# ATmegaS128 device description
Architecture: AVR8; Family: megaAVR
Registers are 8-bit, access not given, no defined reset value unless marked. A register's access mark holds for its fields unless they carry their own. Offsets are from the block's base; [hi:lo] are bit positions; {n}, {i} and the like mark numbered series.

## USART1 — USART
Instances: USART1 0x00
0x98 UBRR1H bits used 3:0 — USART Baud Rate Register High Byte
0x99 UBRR1L — USART Baud Rate Register Low Byte
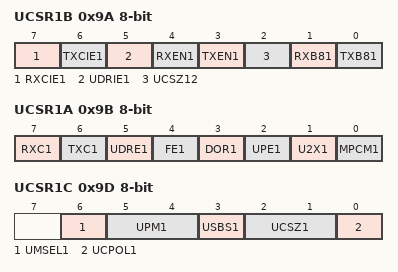
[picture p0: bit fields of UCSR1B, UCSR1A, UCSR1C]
0x9A UCSR1B — USART Control and Status Register B
  [7] RXCIE1 — RX Complete Interrupt Enable
  [6] TXCIE1 — TX Complete Interrupt Enable
  [5] UDRIE1 — USART Data register Empty Interrupt Enable
  [4] RXEN1 — Receiver Enable
  [3] TXEN1 — Transmitter Enable
  [2] UCSZ12 — Character Size
  [1] RXB81 — Receive Data Bit 8
  [0] TXB81 — Transmit Data Bit 8
0x9B UCSR1A — USART Control and Status Register A
  [7] RXC1 — USART Receive Complete
  [6] TXC1 — USART Transmit Complete
  [5] UDRE1 — USART Data Register Empty
  [4] FE1 — Framing Error
  [3] DOR1 — Data overRun
  [2] UPE1 — Parity Error
  [1] U2X1 — Double the USART transmission speed
  [0] MPCM1 — Multi-processor Communication Mode
0x9C UDR1 — USART I/O Data Register
0x9D UCSR1C — USART Control and Status Register C
  [6] UMSEL1 — USART Mode Select
    0=ASYNCHRONOUS_OPERATION; 1=SYNCHRONOUS_OPERATION
  [5:4] UPM1 — Parity Mode Bits
    0=DISABLED; 2=ENABLED_EVEN_PARITY; 3=ENABLED_ODD_PARITY
  [3] USBS1 — Stop Bit Select
    0=1_BIT; 1=2_BIT
  [2:1] UCSZ1 — Character Size
  [0] UCPOL1 — Clock Polarity

## CPU — CPU Registers
Instances: CPU 0x00
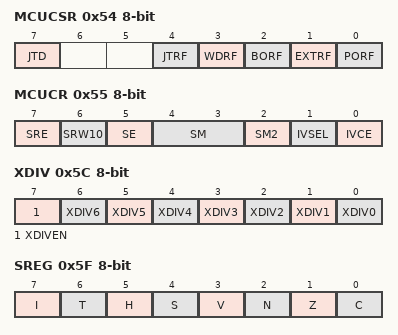
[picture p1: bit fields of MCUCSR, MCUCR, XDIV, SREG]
0x54 MCUCSR — MCU Control And Status Register
  [7] JTD — JTAG Interface Disable
  [4] JTRF — JTAG Reset Flag
  [3] WDRF — Watchdog Reset Flag
  [2] BORF — Brown-out Reset Flag
  [1] EXTRF — External Reset Flag
  [0] PORF — Power-on reset flag
0x55 MCUCR — MCU Control Register
  [7] SRE — External SRAM Enable
  [6] SRW10 — External SRAM Wait State Select
  [5] SE — Sleep Enable
  [4:3] SM — Sleep Mode Select
  [2] SM2 — Sleep Mode Select
    0=IDLE; 2=ADC (ADC Noise Reduction (If Available)); 4=PDOWN (Power Down); 6=PSAVE (Power Save); 5=STDBY (Standby); 7=ESTDBY (Extended Standby)
  [1] IVSEL — Interrupt Vector Select
  [0] IVCE — Interrupt Vector Change Enable
0x5B RAMPZ — RAM Page Z Select Register
  [0] RAMPZ0 — RAM Page Z Select Register Bit 0
0x5C XDIV — XTAL Divide Control Register
  [7] XDIVEN — XTAL Divide Enable
  [n] XDIV{n} (n=0..6) — XTAL Divide Select Bit {n}
0x5D SP 16-bit — Stack Pointer
0x5F SREG — Status Register
  [7] I — Global Interrupt Enable
  [6] T — Bit Copy Storage
  [5] H — Half Carry Flag
  [4] S — Sign Bit
  [3] V — Two's Complement Overflow Flag
  [2] N — Negative Flag
  [1] Z — Zero Flag
  [0] C — Carry Flag
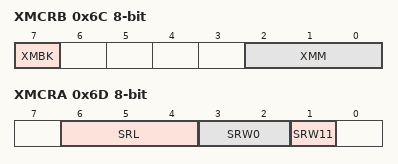
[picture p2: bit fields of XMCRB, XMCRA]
0x6C XMCRB — External Memory Control Register B
  [7] XMBK — External Memory Bus Keeper Enable
  [2:0] XMM — External Memory High Mask
0x6D XMCRA — External Memory Control Register A
  [6:4] SRL — Wait state page limit
    0=LS_N_A_US_0X1100_0XFFFF; 1=LS_0X1100_0X1FFF_US_0X2000_0XFFFF; 2=LS_0X1100_0X3FFF_US_0X4000_0XFFFF; 3=LS_0X1100_0X5FFF_US_0X6000_0XFFFF; 4=LS_0X1100_0X7FFF_US_0X8000_0XFFFF; 5=LS_0X1100_0X9FFF_US_0XA000_0XFFFF; 6=LS_0X1100_0XBFFF_US_0XC000_0XFFFF; 7=LS_0X1100_0XDFFF_US_0XE000_0XFFFF
  [3:2] SRW0 — Wait state select bit lower page
    0=NO_WAIT_STATES; 1=WAIT_ONE_CYCLE_DURING_READ_WRITE_STROBE; 2=WAIT_TWO_CYCLES_DURING_READ_WRITE_STROBE; 3=WAIT_TWO_CYCLES_DURING_READ_WRITE_AND_WAIT_ONE_CYCLE_BEFORE_DRIVING_OUT_NEW_ADDRESS
  [1] SRW11 — Wait state select bit upper page
0x6F OSCCAL — Oscillator Calibration Value
  [7:0] OSCCAL — Oscillator Calibration
Value list OSCCAL_VALUE_ADDRESSES: 0=1_0_MHz_; 1=2_0_MHz_; 2=4_0_MHz_; 3=8_0_MHz

## BOOT_LOAD — Bootloader
Instances: BOOT_LOAD 0x00
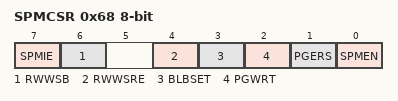
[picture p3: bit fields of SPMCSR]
0x68 SPMCSR — Store Program Memory Control Register
  [7] SPMIE — SPM Interrupt Enable
  [6] RWWSB — Read While Write Section Busy
  [4] RWWSRE — Read While Write section read enable
  [3] BLBSET — Boot Lock Bit Set
  [2] PGWRT — Page Write
  [1] PGERS — Page Erase
  [0] SPMEN — Store Program Memory Enable
